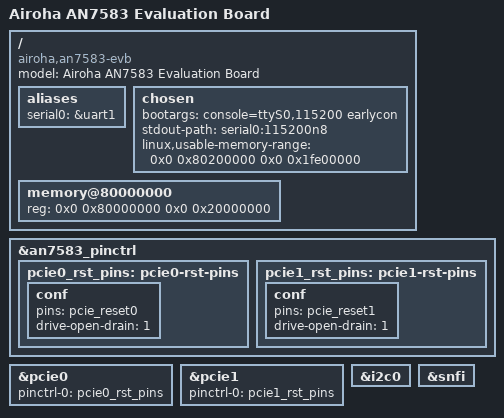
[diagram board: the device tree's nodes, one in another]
// SPDX-License-Identifier: (GPL-2.0-only OR BSD-2-Clause)
/dts-v1/;

/* Bootloader installs ATF here */
/memreserve/ 0x80000000 0x200000;

#include <dt-bindings/leds/common.h>
#include <dt-bindings/gpio/gpio.h>
#include <dt-bindings/input/input.h>
#include "an7583.dtsi"

/ {
	model = "Airoha AN7583 Evaluation Board";
	compatible = "airoha,an7583-evb", "airoha,an7583", "airoha,en7583";

	aliases {
		serial0 = &uart1;
	};

	chosen {
		bootargs = "console=ttyS0,115200 earlycon";
		stdout-path = "serial0:115200n8";
		linux,usable-memory-range = <0x0 0x80200000 0x0 0x1fe00000>;
	};

	/* When running as a first-stage bootloader this isn't filled in automatically */
	memory@80000000 {
		device_type = "memory";
		reg = <0x0 0x80000000 0x0 0x20000000>;
	};
};

&an7583_pinctrl {
	pcie0_rst_pins: pcie0-rst-pins {
		conf {
			pins = "pcie_reset0";
			drive-open-drain = <1>;
		};
	};

	pcie1_rst_pins: pcie1-rst-pins {
		conf {
			pins = "pcie_reset1";
			drive-open-drain = <1>;
		};
	};
};

&pcie0 {
	pinctrl-names = "default";
	pinctrl-0 = <&pcie0_rst_pins>;
	status = "okay";
};

&pcie1 {
	pinctrl-names = "default";
	pinctrl-0 = <&pcie1_rst_pins>;
	status = "okay";
};

&i2c0 {
	status = "okay";
};

&snfi {
	status = "okay";
};
